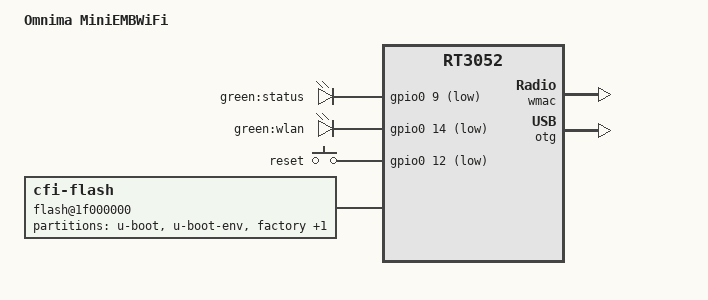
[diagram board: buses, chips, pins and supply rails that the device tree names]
#include "rt3050.dtsi"

#include <dt-bindings/gpio/gpio.h>
#include <dt-bindings/input/input.h>

/ {
	compatible = "omnima,miniembwifi", "ralink,rt3052-soc";
	model = "Omnima MiniEMBWiFi";

	aliases {
		led-boot = &led_status;
		led-failsafe = &led_status;
		led-running = &led_status;
		led-upgrade = &led_status;
	};

	leds {
		compatible = "gpio-leds";

		led_status: status {
			label = "green:status";
			gpios = <&gpio0 9 GPIO_ACTIVE_LOW>;
		};

		wlan {
			label = "green:wlan";
			gpios = <&gpio0 14 GPIO_ACTIVE_LOW>;
		};
	};

	keys {
		compatible = "gpio-keys-polled";
		poll-interval = <20>;

		reset {
			label = "reset";
			gpios = <&gpio0 12 GPIO_ACTIVE_LOW>;
			linux,code = <KEY_RESTART>;
		};
	};

	flash@1f000000 {
		compatible = "cfi-flash";
		reg = <0x1f000000 0x800000>;
		bank-width = <2>;
		device-width = <2>;

		partitions {
			compatible = "fixed-partitions";
			#address-cells = <1>;
			#size-cells = <1>;

			partition@0 {
				label = "u-boot";
				reg = <0x0 0x30000>;
				read-only;
			};

			partition@30000 {
				label = "u-boot-env";
				reg = <0x30000 0x10000>;
				read-only;
			};

			factory: partition@40000 {
				label = "factory";
				reg = <0x40000 0x10000>;
				read-only;
			};

			partition@50000 {
				compatible = "denx,uimage";
				label = "firmware";
				reg = <0x50000 0x7b0000>;
			};
		};
	};
};

&state_default {
	gpio {
		groups = "spi", "i2c", "jtag", "rgmii", "mdio", "uartf";
		function = "gpio";
	};
};

&ethernet {
	mtd-mac-address = <&factory 0x28>;
};

&esw {
	mediatek,portmap = <0x2f>;
};

&wmac {
	ralink,mtd-eeprom = <&factory 0x0>;
};

&otg {
	status = "okay";
};
